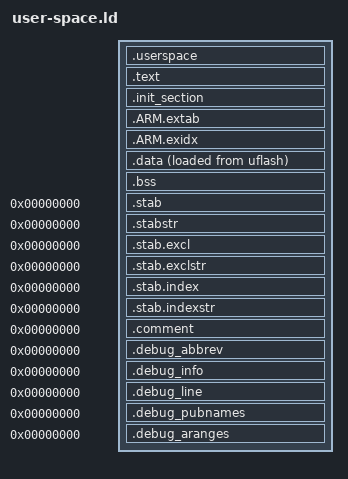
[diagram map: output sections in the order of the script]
/****************************************************************************
 * boards/spike-prime-hub/scripts/user-space.ld
 *
 * SPDX-License-Identifier: Apache-2.0
 *
 * Licensed to the Apache Software Foundation (ASF) under one or more
 * contributor license agreements.  See the NOTICE file distributed with
 * this work for additional information regarding copyright ownership.  The
 * ASF licenses this file to you under the Apache License, Version 2.0 (the
 * "License"); you may not use this file except in compliance with the
 * License.  You may obtain a copy of the License at
 *
 *   http://www.apache.org/licenses/LICENSE-2.0
 *
 * Unless required by applicable law or agreed to in writing, software
 * distributed under the License is distributed on an "AS IS" BASIS, WITHOUT
 * WARRANTIES OR CONDITIONS OF ANY KIND, either express or implied.  See the
 * License for the specific language governing permissions and limitations
 * under the License.
 *
 ****************************************************************************/

/* NOTE:  This depends on the memory.ld script having been included prior to
 * this script.
 */

/* Make sure that the critical memory management functions are in user-space.
 * The user heap memory manager will reside in user-space but be usable both
 * by kernel- and user-space code.
 */

EXTERN(umm_initialize)
EXTERN(umm_addregion)

EXTERN(malloc)
EXTERN(realloc)
EXTERN(zalloc)
EXTERN(free)

OUTPUT_ARCH(arm)
SECTIONS
{
    .userspace : {
        KEEP(*(.userspace))
    } > uflash

    .text : {
        _stext = ABSOLUTE(.);
        *(.text .text.*)
        *(.fixup)
        *(.gnu.warning)
        *(.rodata .rodata.*)
        *(.gnu.linkonce.t.*)
        *(.glue_7)
        *(.glue_7t)
        *(.got)
        *(.gcc_except_table)
        *(.gnu.linkonce.r.*)
        _etext = ABSOLUTE(.);
    } > uflash

    .init_section : ALIGN(4) {
        _sinit = ABSOLUTE(.);
        KEEP(*(SORT_BY_INIT_PRIORITY(.init_array.*) SORT_BY_INIT_PRIORITY(.ctors.*)))
        KEEP(*(.init_array EXCLUDE_FILE(*crtbegin.o *crtbegin?.o *crtend.o *crtend?.o) .ctors))
        _einit = ABSOLUTE(.);
    } > uflash

    .ARM.extab : ALIGN(4) {
        *(.ARM.extab*)
    } > uflash

    .ARM.exidx : ALIGN(4) {
        __exidx_start = ABSOLUTE(.);
        *(.ARM.exidx*)
        __exidx_end = ABSOLUTE(.);
    } > uflash

    _eronly = ABSOLUTE(.);

    .data : ALIGN(4) {
        _sdata = ABSOLUTE(.);
        *(.data .data.*)
        *(.gnu.linkonce.d.*)
        CONSTRUCTORS
        . = ALIGN(4);
        _edata = ABSOLUTE(.);
    } > usram AT > uflash

    .bss : ALIGN(4) {
        _sbss = ABSOLUTE(.);
        *(.bss .bss.*)
        *(.gnu.linkonce.b.*)
        *(COMMON)
        . = ALIGN(4);
        _ebss = ABSOLUTE(.);
    } > usram

    /* Stabs debugging sections. */

    .stab 0 : { *(.stab) }
    .stabstr 0 : { *(.stabstr) }
    .stab.excl 0 : { *(.stab.excl) }
    .stab.exclstr 0 : { *(.stab.exclstr) }
    .stab.index 0 : { *(.stab.index) }
    .stab.indexstr 0 : { *(.stab.indexstr) }
    .comment 0 : { *(.comment) }
    .debug_abbrev 0 : { *(.debug_abbrev) }
    .debug_info 0 : { *(.debug_info) }
    .debug_line 0 : { *(.debug_line) }
    .debug_pubnames 0 : { *(.debug_pubnames) }
    .debug_aranges 0 : { *(.debug_aranges) }
}

/* Issue #98: usram is 128 KB at 0x20020000..0x20040000.  Fail the link if
 * .data/.bss escape that range so the runtime never has to deal with a
 * us_bssend outside the MPU-exposed usram region.
 */
ASSERT(_sdata >= 0x20020000,
       "user .data starts before usram base 0x20020000")
ASSERT(_ebss  <= 0x20040000,
       "user .data/.bss exceeds 128 KB usram (0x20020000..0x20040000)")
